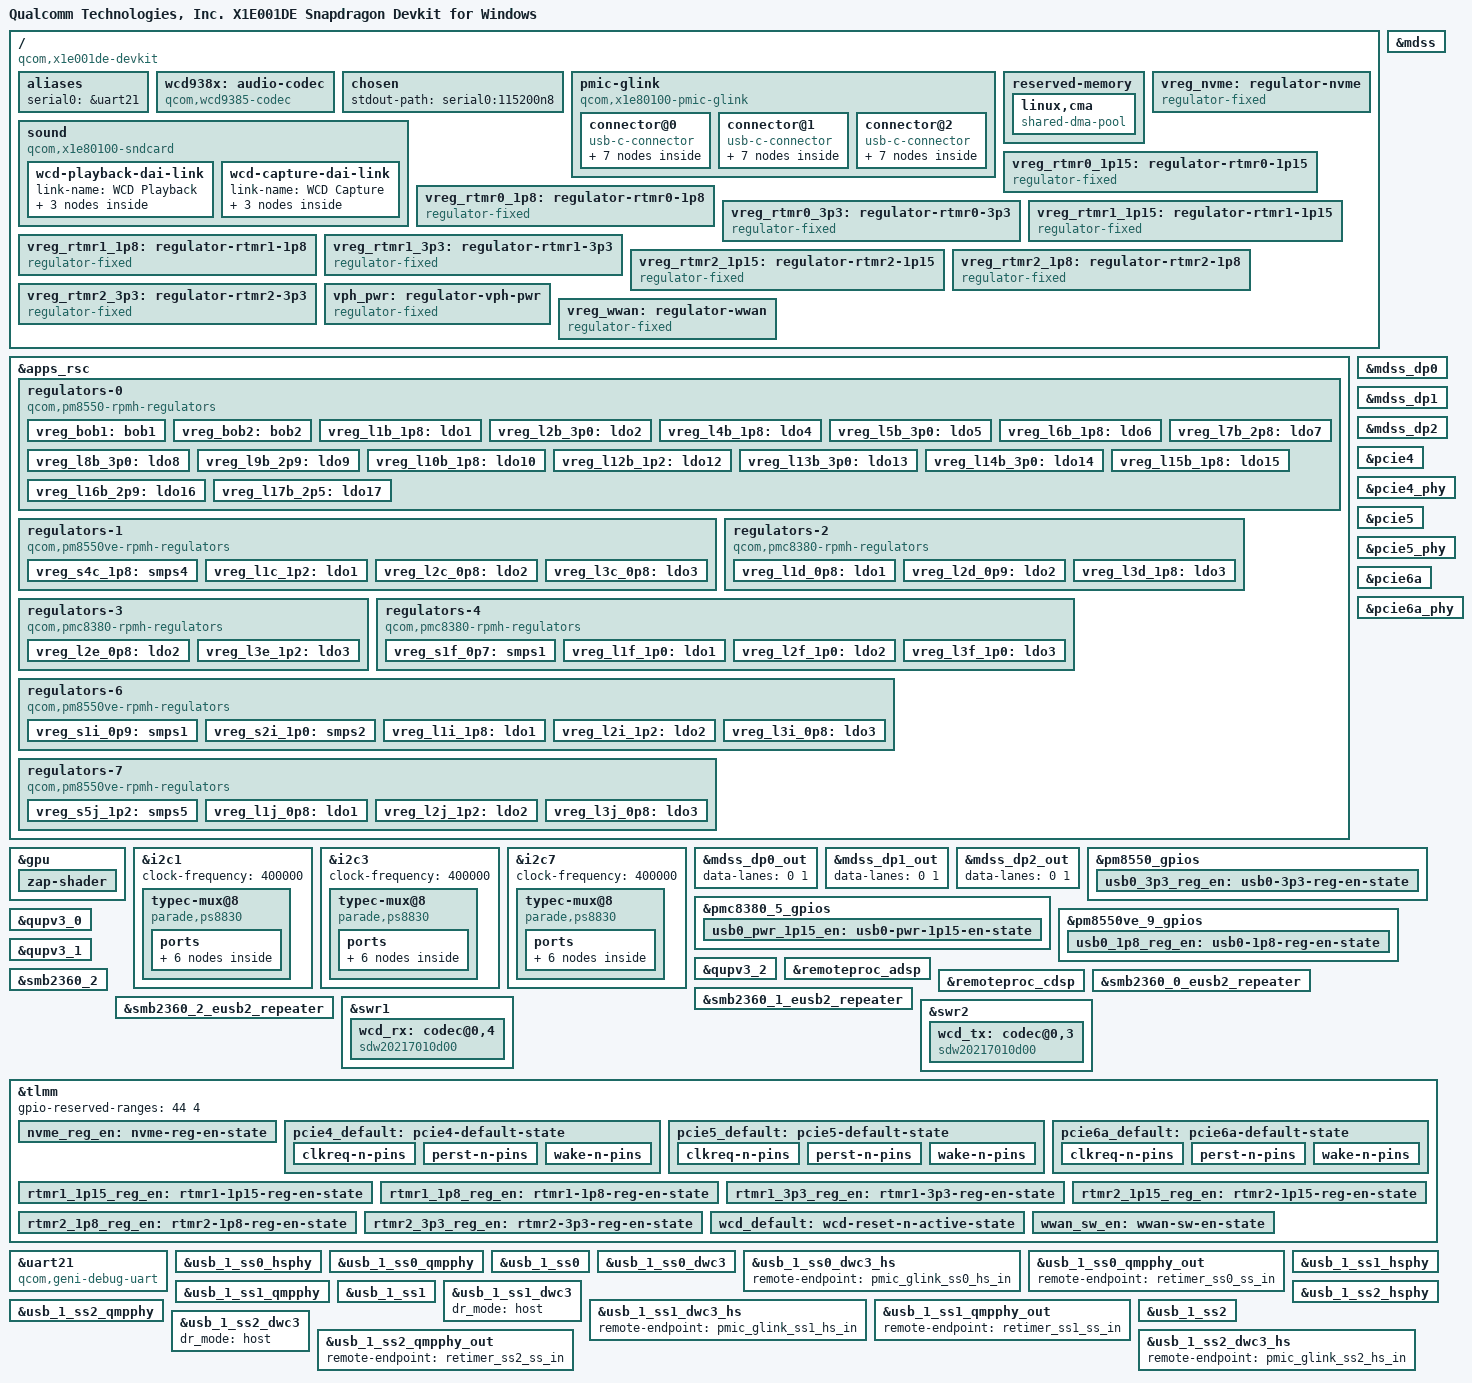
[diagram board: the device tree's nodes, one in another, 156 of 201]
// SPDX-License-Identifier: BSD-3-Clause
/*
 * Copyright (c) 2024 Qualcomm Innovation Center, Inc. All rights reserved.
 */

/dts-v1/;

#include <dt-bindings/gpio/gpio.h>
#include <dt-bindings/regulator/qcom,rpmh-regulator.h>

#include "x1e80100.dtsi"
#include "x1e80100-pmics.dtsi"

/ {
	model = "Qualcomm Technologies, Inc. X1E001DE Snapdragon Devkit for Windows";
	compatible = "qcom,x1e001de-devkit", "qcom,x1e001de", "qcom,x1e80100";

	aliases {
		serial0 = &uart21;
	};

	wcd938x: audio-codec {
		compatible = "qcom,wcd9385-codec";

		pinctrl-names = "default";
		pinctrl-0 = <&wcd_default>;

		qcom,micbias1-microvolt = <1800000>;
		qcom,micbias2-microvolt = <1800000>;
		qcom,micbias3-microvolt = <1800000>;
		qcom,micbias4-microvolt = <1800000>;
		qcom,mbhc-buttons-vthreshold-microvolt = <75000 150000 237000 500000 500000 500000 500000 500000>;
		qcom,mbhc-headset-vthreshold-microvolt = <1700000>;
		qcom,mbhc-headphone-vthreshold-microvolt = <50000>;
		qcom,rx-device = <&wcd_rx>;
		qcom,tx-device = <&wcd_tx>;

		reset-gpios = <&tlmm 191 GPIO_ACTIVE_LOW>;

		vdd-buck-supply = <&vreg_l15b_1p8>;
		vdd-rxtx-supply = <&vreg_l15b_1p8>;
		vdd-io-supply = <&vreg_l15b_1p8>;
		vdd-mic-bias-supply = <&vreg_bob1>;

		#sound-dai-cells = <1>;
	};

	chosen {
		stdout-path = "serial0:115200n8";
	};

	pmic-glink {
		compatible = "qcom,x1e80100-pmic-glink",
			     "qcom,sm8550-pmic-glink",
			     "qcom,pmic-glink";
		#address-cells = <1>;
		#size-cells = <0>;
		orientation-gpios = <&tlmm 121 GPIO_ACTIVE_HIGH>,
				    <&tlmm 123 GPIO_ACTIVE_HIGH>,
				    <&tlmm 125 GPIO_ACTIVE_HIGH>;

		/* Back panel port closer to the RJ45 connector */
		connector@0 {
			compatible = "usb-c-connector";
			reg = <0>;
			power-role = "dual";
			data-role = "dual";

			ports {
				#address-cells = <1>;
				#size-cells = <0>;

				port@0 {
					reg = <0>;

					pmic_glink_ss0_hs_in: endpoint {
						remote-endpoint = <&usb_1_ss0_dwc3_hs>;
					};
				};

				port@1 {
					reg = <1>;

					pmic_glink_ss0_ss_in: endpoint {
						remote-endpoint = <&retimer_ss0_ss_out>;
					};
				};

				port@2 {
					reg = <2>;

					pmic_glink_ss0_con_sbu_in: endpoint {
						remote-endpoint = <&retimer_ss0_con_sbu_out>;
					};
				};
			};
		};

		/* Back panel port closer to the audio jack */
		connector@1 {
			compatible = "usb-c-connector";
			reg = <1>;
			power-role = "dual";
			data-role = "host";

			ports {
				#address-cells = <1>;
				#size-cells = <0>;

				port@0 {
					reg = <0>;

					pmic_glink_ss1_hs_in: endpoint {
						remote-endpoint = <&usb_1_ss1_dwc3_hs>;
					};
				};

				port@1 {
					reg = <1>;

					pmic_glink_ss1_ss_in: endpoint {
						remote-endpoint = <&retimer_ss1_ss_out>;
					};
				};

				port@2 {
					reg = <2>;

					pmic_glink_ss1_con_sbu_in: endpoint {
						remote-endpoint = <&retimer_ss1_con_sbu_out>;
					};
				};
			};
		};

		/* Front panel port */
		connector@2 {
			compatible = "usb-c-connector";
			reg = <2>;
			power-role = "dual";
			data-role = "host";

			ports {
				#address-cells = <1>;
				#size-cells = <0>;

				port@0 {
					reg = <0>;

					pmic_glink_ss2_hs_in: endpoint {
						remote-endpoint = <&usb_1_ss2_dwc3_hs>;
					};
				};

				port@1 {
					reg = <1>;

					pmic_glink_ss2_ss_in: endpoint {
						remote-endpoint = <&retimer_ss2_ss_out>;
					};
				};

				port@2 {
					reg = <2>;

					pmic_glink_ss2_con_sbu_in: endpoint {
						remote-endpoint = <&retimer_ss2_con_sbu_out>;
					};
				};
			};
		};
	};

	reserved-memory {
		linux,cma {
			compatible = "shared-dma-pool";
			size = <0x0 0x8000000>;
			reusable;
			linux,cma-default;
		};
	};

	sound {
		compatible = "qcom,x1e80100-sndcard";
		model = "X1E001DE-DEVKIT";
		audio-routing = "IN1_HPHL", "HPHL_OUT",
				"IN2_HPHR", "HPHR_OUT",
				"AMIC2", "MIC BIAS2",
				"TX SWR_INPUT1", "ADC2_OUTPUT";

		wcd-playback-dai-link {
			link-name = "WCD Playback";

			cpu {
				sound-dai = <&q6apmbedai RX_CODEC_DMA_RX_0>;
			};

			codec {
				sound-dai = <&wcd938x 0>, <&swr1 0>, <&lpass_rxmacro 0>;
			};

			platform {
				sound-dai = <&q6apm>;
			};
		};

		wcd-capture-dai-link {
			link-name = "WCD Capture";

			cpu {
				sound-dai = <&q6apmbedai TX_CODEC_DMA_TX_3>;
			};

			codec {
				sound-dai = <&wcd938x 1>, <&swr2 1>, <&lpass_txmacro 0>;
			};

			platform {
				sound-dai = <&q6apm>;
			};
		};
	};

	vreg_nvme: regulator-nvme {
		compatible = "regulator-fixed";

		regulator-name = "VREG_NVME_3P3";
		regulator-min-microvolt = <3300000>;
		regulator-max-microvolt = <3300000>;

		gpio = <&tlmm 18 GPIO_ACTIVE_HIGH>;
		enable-active-high;

		pinctrl-names = "default";
		pinctrl-0 = <&nvme_reg_en>;

		regulator-boot-on;
	};

	vreg_rtmr0_1p15: regulator-rtmr0-1p15 {
		compatible = "regulator-fixed";

		regulator-name = "VREG_RTMR0_1P15";
		regulator-min-microvolt = <1150000>;
		regulator-max-microvolt = <1150000>;

		gpio = <&pmc8380_5_gpios 8 GPIO_ACTIVE_HIGH>;
		enable-active-high;

		pinctrl-0 = <&usb0_pwr_1p15_en>;
		pinctrl-names = "default";

		regulator-boot-on;
	};

	vreg_rtmr0_1p8: regulator-rtmr0-1p8 {
		compatible = "regulator-fixed";

		regulator-name = "VREG_RTMR0_1P8";
		regulator-min-microvolt = <1800000>;
		regulator-max-microvolt = <1800000>;

		gpio = <&pm8550ve_9_gpios 8 GPIO_ACTIVE_HIGH>;
		enable-active-high;

		pinctrl-0 = <&usb0_1p8_reg_en>;
		pinctrl-names = "default";

		regulator-boot-on;
	};

	vreg_rtmr0_3p3: regulator-rtmr0-3p3 {
		compatible = "regulator-fixed";

		regulator-name = "VREG_RTMR0_3P3";
		regulator-min-microvolt = <3300000>;
		regulator-max-microvolt = <3300000>;

		gpio = <&pm8550_gpios 11 GPIO_ACTIVE_HIGH>;
		enable-active-high;

		pinctrl-0 = <&usb0_3p3_reg_en>;
		pinctrl-names = "default";

		regulator-boot-on;
	};

	vreg_rtmr1_1p15: regulator-rtmr1-1p15 {
		compatible = "regulator-fixed";

		regulator-name = "VREG_RTMR1_1P15";
		regulator-min-microvolt = <1150000>;
		regulator-max-microvolt = <1150000>;

		gpio = <&tlmm 188 GPIO_ACTIVE_HIGH>;
		enable-active-high;

		pinctrl-0 = <&rtmr1_1p15_reg_en>;
		pinctrl-names = "default";

		regulator-boot-on;
	};

	vreg_rtmr1_1p8: regulator-rtmr1-1p8 {
		compatible = "regulator-fixed";

		regulator-name = "VREG_RTMR1_1P8";
		regulator-min-microvolt = <1800000>;
		regulator-max-microvolt = <1800000>;

		gpio = <&tlmm 175 GPIO_ACTIVE_HIGH>;
		enable-active-high;

		pinctrl-0 = <&rtmr1_1p8_reg_en>;
		pinctrl-names = "default";

		regulator-boot-on;
	};

	vreg_rtmr1_3p3: regulator-rtmr1-3p3 {
		compatible = "regulator-fixed";

		regulator-name = "VREG_RTMR1_3P3";
		regulator-min-microvolt = <3300000>;
		regulator-max-microvolt = <3300000>;

		gpio = <&tlmm 186 GPIO_ACTIVE_HIGH>;
		enable-active-high;

		pinctrl-0 = <&rtmr1_3p3_reg_en>;
		pinctrl-names = "default";

		regulator-boot-on;
	};

	vreg_rtmr2_1p15: regulator-rtmr2-1p15 {
		compatible = "regulator-fixed";

		regulator-name = "VREG_RTMR2_1P15";
		regulator-min-microvolt = <1150000>;
		regulator-max-microvolt = <1150000>;

		gpio = <&tlmm 189 GPIO_ACTIVE_HIGH>;
		enable-active-high;

		pinctrl-0 = <&rtmr2_1p15_reg_en>;
		pinctrl-names = "default";

		regulator-boot-on;
	};

	vreg_rtmr2_1p8: regulator-rtmr2-1p8 {
		compatible = "regulator-fixed";

		regulator-name = "VREG_RTMR2_1P8";
		regulator-min-microvolt = <1800000>;
		regulator-max-microvolt = <1800000>;

		gpio = <&tlmm 126 GPIO_ACTIVE_HIGH>;
		enable-active-high;

		pinctrl-0 = <&rtmr2_1p8_reg_en>;
		pinctrl-names = "default";

		regulator-boot-on;
	};

	vreg_rtmr2_3p3: regulator-rtmr2-3p3 {
		compatible = "regulator-fixed";

		regulator-name = "VREG_RTMR2_3P3";
		regulator-min-microvolt = <3300000>;
		regulator-max-microvolt = <3300000>;

		gpio = <&tlmm 187 GPIO_ACTIVE_HIGH>;
		enable-active-high;

		pinctrl-0 = <&rtmr2_3p3_reg_en>;
		pinctrl-names = "default";

		regulator-boot-on;
	};

	vph_pwr: regulator-vph-pwr {
		compatible = "regulator-fixed";

		regulator-name = "vph_pwr";
		regulator-min-microvolt = <3700000>;
		regulator-max-microvolt = <3700000>;

		regulator-always-on;
		regulator-boot-on;
	};

	vreg_wwan: regulator-wwan {
		compatible = "regulator-fixed";

		regulator-name = "SDX_VPH_PWR";
		regulator-min-microvolt = <3300000>;
		regulator-max-microvolt = <3300000>;

		gpio = <&tlmm 221 GPIO_ACTIVE_HIGH>;
		enable-active-high;

		pinctrl-0 = <&wwan_sw_en>;
		pinctrl-names = "default";

		regulator-boot-on;
	};
};

&apps_rsc {
	regulators-0 {
		compatible = "qcom,pm8550-rpmh-regulators";
		qcom,pmic-id = "b";

		vdd-bob1-supply = <&vph_pwr>;
		vdd-bob2-supply = <&vph_pwr>;
		vdd-l1-l4-l10-supply = <&vreg_s4c_1p8>;
		vdd-l2-l13-l14-supply = <&vreg_bob1>;
		vdd-l5-l16-supply = <&vreg_bob1>;
		vdd-l6-l7-supply = <&vreg_bob2>;
		vdd-l8-l9-supply = <&vreg_bob1>;
		vdd-l12-supply = <&vreg_s5j_1p2>;
		vdd-l15-supply = <&vreg_s4c_1p8>;
		vdd-l17-supply = <&vreg_bob2>;

		vreg_bob1: bob1 {
			regulator-name = "vreg_bob1";
			regulator-min-microvolt = <3008000>;
			regulator-max-microvolt = <3960000>;
			regulator-initial-mode = <RPMH_REGULATOR_MODE_HPM>;
		};

		vreg_bob2: bob2 {
			regulator-name = "vreg_bob2";
			regulator-min-microvolt = <2504000>;
			regulator-max-microvolt = <3008000>;
			regulator-initial-mode = <RPMH_REGULATOR_MODE_HPM>;
		};

		vreg_l1b_1p8: ldo1 {
			regulator-name = "vreg_l1b_1p8";
			regulator-min-microvolt = <1800000>;
			regulator-max-microvolt = <1800000>;
			regulator-initial-mode = <RPMH_REGULATOR_MODE_HPM>;
		};

		vreg_l2b_3p0: ldo2 {
			regulator-name = "vreg_l2b_3p0";
			regulator-min-microvolt = <3072000>;
			regulator-max-microvolt = <3100000>;
			regulator-initial-mode = <RPMH_REGULATOR_MODE_HPM>;
		};

		vreg_l4b_1p8: ldo4 {
			regulator-name = "vreg_l4b_1p8";
			regulator-min-microvolt = <1800000>;
			regulator-max-microvolt = <1800000>;
			regulator-initial-mode = <RPMH_REGULATOR_MODE_HPM>;
		};

		vreg_l5b_3p0: ldo5 {
			regulator-name = "vreg_l5b_3p0";
			regulator-min-microvolt = <3000000>;
			regulator-max-microvolt = <3000000>;
			regulator-initial-mode = <RPMH_REGULATOR_MODE_HPM>;
		};

		vreg_l6b_1p8: ldo6 {
			regulator-name = "vreg_l6b_1p8";
			regulator-min-microvolt = <1800000>;
			regulator-max-microvolt = <2960000>;
			regulator-initial-mode = <RPMH_REGULATOR_MODE_HPM>;
		};

		vreg_l7b_2p8: ldo7 {
			regulator-name = "vreg_l7b_2p8";
			regulator-min-microvolt = <2800000>;
			regulator-max-microvolt = <2800000>;
			regulator-initial-mode = <RPMH_REGULATOR_MODE_HPM>;
		};

		vreg_l8b_3p0: ldo8 {
			regulator-name = "vreg_l8b_3p0";
			regulator-min-microvolt = <3072000>;
			regulator-max-microvolt = <3072000>;
			regulator-initial-mode = <RPMH_REGULATOR_MODE_HPM>;
		};

		vreg_l9b_2p9: ldo9 {
			regulator-name = "vreg_l9b_2p9";
			regulator-min-microvolt = <2960000>;
			regulator-max-microvolt = <2960000>;
			regulator-initial-mode = <RPMH_REGULATOR_MODE_HPM>;
		};

		vreg_l10b_1p8: ldo10 {
			regulator-name = "vreg_l10b_1p8";
			regulator-min-microvolt = <1800000>;
			regulator-max-microvolt = <1800000>;
			regulator-initial-mode = <RPMH_REGULATOR_MODE_HPM>;
		};

		vreg_l12b_1p2: ldo12 {
			regulator-name = "vreg_l12b_1p2";
			regulator-min-microvolt = <1200000>;
			regulator-max-microvolt = <1200000>;
			regulator-initial-mode = <RPMH_REGULATOR_MODE_HPM>;
		};

		vreg_l13b_3p0: ldo13 {
			regulator-name = "vreg_l13b_3p0";
			regulator-min-microvolt = <3072000>;
			regulator-max-microvolt = <3100000>;
			regulator-initial-mode = <RPMH_REGULATOR_MODE_HPM>;
		};

		vreg_l14b_3p0: ldo14 {
			regulator-name = "vreg_l14b_3p0";
			regulator-min-microvolt = <3072000>;
			regulator-max-microvolt = <3072000>;
			regulator-initial-mode = <RPMH_REGULATOR_MODE_HPM>;
		};

		vreg_l15b_1p8: ldo15 {
			regulator-name = "vreg_l15b_1p8";
			regulator-min-microvolt = <1800000>;
			regulator-max-microvolt = <1800000>;
			regulator-initial-mode = <RPMH_REGULATOR_MODE_HPM>;
		};

		vreg_l16b_2p9: ldo16 {
			regulator-name = "vreg_l16b_2p9";
			regulator-min-microvolt = <2912000>;
			regulator-max-microvolt = <2912000>;
			regulator-initial-mode = <RPMH_REGULATOR_MODE_HPM>;
		};

		vreg_l17b_2p5: ldo17 {
			regulator-name = "vreg_l17b_2p5";
			regulator-min-microvolt = <2504000>;
			regulator-max-microvolt = <2504000>;
			regulator-initial-mode = <RPMH_REGULATOR_MODE_HPM>;
		};
	};

	regulators-1 {
		compatible = "qcom,pm8550ve-rpmh-regulators";
		qcom,pmic-id = "c";

		vdd-l1-supply = <&vreg_s5j_1p2>;
		vdd-l2-supply = <&vreg_s1f_0p7>;
		vdd-l3-supply = <&vreg_s1f_0p7>;
		vdd-s4-supply = <&vph_pwr>;

		vreg_s4c_1p8: smps4 {
			regulator-name = "vreg_s4c_1p8";
			regulator-min-microvolt = <1856000>;
			regulator-max-microvolt = <2000000>;
			regulator-initial-mode = <RPMH_REGULATOR_MODE_HPM>;
		};

		vreg_l1c_1p2: ldo1 {
			regulator-name = "vreg_l1c_1p2";
			regulator-min-microvolt = <1200000>;
			regulator-max-microvolt = <1200000>;
			regulator-initial-mode = <RPMH_REGULATOR_MODE_HPM>;
		};

		vreg_l2c_0p8: ldo2 {
			regulator-name = "vreg_l2c_0p8";
			regulator-min-microvolt = <880000>;
			regulator-max-microvolt = <920000>;
			regulator-initial-mode = <RPMH_REGULATOR_MODE_HPM>;
		};

		vreg_l3c_0p8: ldo3 {
			regulator-name = "vreg_l3c_0p8";
			regulator-min-microvolt = <880000>;
			regulator-max-microvolt = <920000>;
			regulator-initial-mode = <RPMH_REGULATOR_MODE_HPM>;
		};
	};

	regulators-2 {
		compatible = "qcom,pmc8380-rpmh-regulators";
		qcom,pmic-id = "d";

		vdd-l1-supply = <&vreg_s1f_0p7>;
		vdd-l2-supply = <&vreg_s1f_0p7>;
		vdd-l3-supply = <&vreg_s4c_1p8>;
		vdd-s1-supply = <&vph_pwr>;

		vreg_l1d_0p8: ldo1 {
			regulator-name = "vreg_l1d_0p8";
			regulator-min-microvolt = <880000>;
			regulator-max-microvolt = <920000>;
			regulator-initial-mode = <RPMH_REGULATOR_MODE_HPM>;
		};

		vreg_l2d_0p9: ldo2 {
			regulator-name = "vreg_l2d_0p9";
			regulator-min-microvolt = <912000>;
			regulator-max-microvolt = <920000>;
			regulator-initial-mode = <RPMH_REGULATOR_MODE_HPM>;
		};

		vreg_l3d_1p8: ldo3 {
			regulator-name = "vreg_l3d_1p8";
			regulator-min-microvolt = <1800000>;
			regulator-max-microvolt = <1800000>;
			regulator-initial-mode = <RPMH_REGULATOR_MODE_HPM>;
		};
	};

	regulators-3 {
		compatible = "qcom,pmc8380-rpmh-regulators";
		qcom,pmic-id = "e";

		vdd-l2-supply = <&vreg_s1f_0p7>;
		vdd-l3-supply = <&vreg_s5j_1p2>;

		vreg_l2e_0p8: ldo2 {
			regulator-name = "vreg_l2e_0p8";
			regulator-min-microvolt = <880000>;
			regulator-max-microvolt = <920000>;
			regulator-initial-mode = <RPMH_REGULATOR_MODE_HPM>;
		};

		vreg_l3e_1p2: ldo3 {
			regulator-name = "vreg_l3e_1p2";
			regulator-min-microvolt = <1200000>;
			regulator-max-microvolt = <1200000>;
			regulator-initial-mode = <RPMH_REGULATOR_MODE_HPM>;
		};
	};

	regulators-4 {
		compatible = "qcom,pmc8380-rpmh-regulators";
		qcom,pmic-id = "f";

		vdd-l1-supply = <&vreg_s5j_1p2>;
		vdd-l2-supply = <&vreg_s5j_1p2>;
		vdd-l3-supply = <&vreg_s5j_1p2>;
		vdd-s1-supply = <&vph_pwr>;

		vreg_s1f_0p7: smps1 {
			regulator-name = "vreg_s1f_0p7";
			regulator-min-microvolt = <700000>;
			regulator-max-microvolt = <1100000>;
			regulator-initial-mode = <RPMH_REGULATOR_MODE_HPM>;
		};

		vreg_l1f_1p0: ldo1 {
			regulator-name = "vreg_l1f_1p0";
			regulator-min-microvolt = <1024000>;
			regulator-max-microvolt = <1024000>;
			regulator-initial-mode = <RPMH_REGULATOR_MODE_HPM>;
		};

		vreg_l2f_1p0: ldo2 {
			regulator-name = "vreg_l2f_1p0";
			regulator-min-microvolt = <1024000>;
			regulator-max-microvolt = <1024000>;
			regulator-initial-mode = <RPMH_REGULATOR_MODE_HPM>;
		};

		vreg_l3f_1p0: ldo3 {
			regulator-name = "vreg_l3f_1p0";
			regulator-min-microvolt = <1024000>;
			regulator-max-microvolt = <1024000>;
			regulator-initial-mode = <RPMH_REGULATOR_MODE_HPM>;
		};
	};

	regulators-6 {
		compatible = "qcom,pm8550ve-rpmh-regulators";
		qcom,pmic-id = "i";

		vdd-l1-supply = <&vreg_s4c_1p8>;
		vdd-l2-supply = <&vreg_s5j_1p2>;
		vdd-l3-supply = <&vreg_s1f_0p7>;
		vdd-s1-supply = <&vph_pwr>;
		vdd-s2-supply = <&vph_pwr>;

		vreg_s1i_0p9: smps1 {
			regulator-name = "vreg_s1i_0p9";
			regulator-min-microvolt = <900000>;
			regulator-max-microvolt = <920000>;
			regulator-initial-mode = <RPMH_REGULATOR_MODE_HPM>;
		};

		vreg_s2i_1p0: smps2 {
			regulator-name = "vreg_s2i_1p0";
			regulator-min-microvolt = <1000000>;
			regulator-max-microvolt = <1100000>;
			regulator-initial-mode = <RPMH_REGULATOR_MODE_HPM>;
		};

		vreg_l1i_1p8: ldo1 {
			regulator-name = "vreg_l1i_1p8";
			regulator-min-microvolt = <1800000>;
			regulator-max-microvolt = <1800000>;
			regulator-initial-mode = <RPMH_REGULATOR_MODE_HPM>;
		};

		vreg_l2i_1p2: ldo2 {
			regulator-name = "vreg_l2i_1p2";
			regulator-min-microvolt = <1200000>;
			regulator-max-microvolt = <1200000>;
			regulator-initial-mode = <RPMH_REGULATOR_MODE_HPM>;
		};

		vreg_l3i_0p8: ldo3 {
			regulator-name = "vreg_l3i_0p8";
			regulator-min-microvolt = <880000>;
			regulator-max-microvolt = <920000>;
			regulator-initial-mode = <RPMH_REGULATOR_MODE_HPM>;
		};
	};

	regulators-7 {
		compatible = "qcom,pm8550ve-rpmh-regulators";
		qcom,pmic-id = "j";

		vdd-l1-supply = <&vreg_s1f_0p7>;
		vdd-l2-supply = <&vreg_s5j_1p2>;
		vdd-l3-supply = <&vreg_s1f_0p7>;
		vdd-s5-supply = <&vph_pwr>;

		vreg_s5j_1p2: smps5 {
			regulator-name = "vreg_s5j_1p2";
			regulator-min-microvolt = <1256000>;
			regulator-max-microvolt = <1304000>;
			regulator-initial-mode = <RPMH_REGULATOR_MODE_HPM>;
		};

		vreg_l1j_0p8: ldo1 {
			regulator-name = "vreg_l1j_0p8";
			regulator-min-microvolt = <880000>;
			regulator-max-microvolt = <920000>;
			regulator-initial-mode = <RPMH_REGULATOR_MODE_HPM>;
		};

		vreg_l2j_1p2: ldo2 {
			regulator-name = "vreg_l2j_1p2";
			regulator-min-microvolt = <1200000>;
			regulator-max-microvolt = <1200000>;
			regulator-initial-mode = <RPMH_REGULATOR_MODE_HPM>;
		};

		vreg_l3j_0p8: ldo3 {
			regulator-name = "vreg_l3j_0p8";
			regulator-min-microvolt = <880000>;
			regulator-max-microvolt = <920000>;
			regulator-initial-mode = <RPMH_REGULATOR_MODE_HPM>;
		};
	};
};

&gpu {
	status = "okay";

	zap-shader {
		firmware-name = "qcom/x1e80100/Thundercomm/DEVKIT/qcdxkmsuc8380.mbn";
	};
};

&i2c1 {
	clock-frequency = <400000>;

	status = "okay";

	typec-mux@8 {
		compatible = "parade,ps8830";
		reg = <0x08>;

		clocks = <&rpmhcc RPMH_RF_CLK5>;
		clock-names = "xo";

		vdd-supply = <&vreg_rtmr2_1p15>;
		vdd33-supply = <&vreg_rtmr2_3p3>;
		vdd33-cap-supply = <&vreg_rtmr2_3p3>;
		vddar-supply = <&vreg_rtmr2_1p15>;
		vddat-supply = <&vreg_rtmr2_1p15>;
		vddio-supply = <&vreg_rtmr2_1p8>;

		reset-gpios = <&tlmm 185 GPIO_ACTIVE_HIGH>;

		orientation-switch;
		retimer-switch;

		ports {
			#address-cells = <1>;
			#size-cells = <0>;

			port@0 {
				reg = <0>;

				retimer_ss2_ss_out: endpoint {
					remote-endpoint = <&pmic_glink_ss2_ss_in>;
				};
			};

			port@1 {
				reg = <1>;

				retimer_ss2_ss_in: endpoint {
					remote-endpoint = <&usb_1_ss2_qmpphy_out>;
				};
			};

			port@2 {
				reg = <2>;

				retimer_ss2_con_sbu_out: endpoint {
					remote-endpoint = <&pmic_glink_ss2_con_sbu_in>;
				};
			};
		};
	};
};

&i2c3 {
	clock-frequency = <400000>;

	status = "okay";

	typec-mux@8 {
		compatible = "parade,ps8830";
		reg = <0x08>;

		clocks = <&rpmhcc RPMH_RF_CLK3>;
		clock-names = "xo";

		vdd-supply = <&vreg_rtmr0_1p15>;
		vdd33-supply = <&vreg_rtmr0_3p3>;
		vdd33-cap-supply = <&vreg_rtmr0_3p3>;
		vddar-supply = <&vreg_rtmr0_1p15>;
		vddat-supply = <&vreg_rtmr0_1p15>;
		vddio-supply = <&vreg_rtmr0_1p8>;

		reset-gpios = <&pm8550_gpios 10 GPIO_ACTIVE_HIGH>;

		retimer-switch;
		orientation-switch;

		ports {
			#address-cells = <1>;
			#size-cells = <0>;

			port@0 {
				reg = <0>;

				retimer_ss0_ss_out: endpoint {
					remote-endpoint = <&pmic_glink_ss0_ss_in>;
				};
			};

			port@1 {
				reg = <1>;

				retimer_ss0_ss_in: endpoint {
					remote-endpoint = <&usb_1_ss0_qmpphy_out>;
				};
			};

			port@2 {
				reg = <2>;

				retimer_ss0_con_sbu_out: endpoint {
					remote-endpoint = <&pmic_glink_ss0_con_sbu_in>;
				};
			};
		};
	};
};

&i2c7 {
	clock-frequency = <400000>;

	status = "okay";

	typec-mux@8 {
		compatible = "parade,ps8830";
		reg = <0x8>;

		clocks = <&rpmhcc RPMH_RF_CLK4>;
		clock-names = "xo";

		vdd-supply = <&vreg_rtmr1_1p15>;
		vdd33-supply = <&vreg_rtmr1_3p3>;
		vdd33-cap-supply = <&vreg_rtmr1_3p3>;
		vddar-supply = <&vreg_rtmr1_1p15>;
		vddat-supply = <&vreg_rtmr1_1p15>;
		vddio-supply = <&vreg_rtmr1_1p8>;

		reset-gpios = <&tlmm 176 GPIO_ACTIVE_HIGH>;

		retimer-switch;
		orientation-switch;

		ports {
			#address-cells = <1>;
			#size-cells = <0>;

			port@0 {
				reg = <0>;

				retimer_ss1_ss_out: endpoint {
					remote-endpoint = <&pmic_glink_ss1_ss_in>;
				};
			};

			port@1 {
				reg = <1>;

				retimer_ss1_ss_in: endpoint {
					remote-endpoint = <&usb_1_ss1_qmpphy_out>;
				};
			};

			port@2 {
				reg = <2>;

				retimer_ss1_con_sbu_out: endpoint {
					remote-endpoint = <&pmic_glink_ss1_con_sbu_in>;
				};
			};
		};
	};
};

&mdss {
	status = "okay";
};

&mdss_dp0 {
	status = "okay";
};

&mdss_dp0_out {
	data-lanes = <0 1>;
};

&mdss_dp1 {
	status = "okay";
};

&mdss_dp1_out {
	data-lanes = <0 1>;
};

&mdss_dp2 {
	status = "okay";
};

&mdss_dp2_out {
	data-lanes = <0 1>;
};

&pcie4 {
	perst-gpios = <&tlmm 146 GPIO_ACTIVE_LOW>;
	wake-gpios = <&tlmm 148 GPIO_ACTIVE_LOW>;

	pinctrl-0 = <&pcie4_default>;
	pinctrl-names = "default";

	status = "okay";
};

&pcie4_phy {
	vdda-phy-supply = <&vreg_l3i_0p8>;
	vdda-pll-supply = <&vreg_l3e_1p2>;

	status = "okay";
};

&pcie5 {
	perst-gpios = <&tlmm 149 GPIO_ACTIVE_LOW>;
	wake-gpios = <&tlmm 151 GPIO_ACTIVE_LOW>;

	vddpe-3v3-supply = <&vreg_wwan>;

	pinctrl-0 = <&pcie5_default>;
	pinctrl-names = "default";

	status = "okay";
};

&pcie5_phy {
	vdda-phy-supply = <&vreg_l3i_0p8>;
	vdda-pll-supply = <&vreg_l3e_1p2>;

	status = "okay";
};

&pcie6a {
	perst-gpios = <&tlmm 152 GPIO_ACTIVE_LOW>;
	wake-gpios = <&tlmm 154 GPIO_ACTIVE_LOW>;

	vddpe-3v3-supply = <&vreg_nvme>;

	pinctrl-names = "default";
	pinctrl-0 = <&pcie6a_default>;

	status = "okay";
};

&pcie6a_phy {
	vdda-phy-supply = <&vreg_l1d_0p8>;
	vdda-pll-supply = <&vreg_l2j_1p2>;

	status = "okay";
};

&pm8550_gpios {
	usb0_3p3_reg_en: usb0-3p3-reg-en-state {
		pins = "gpio11";
		function = "normal";
	};
};

&pmc8380_5_gpios {
	usb0_pwr_1p15_en: usb0-pwr-1p15-en-state {
		pins = "gpio8";
		function = "normal";
	};
};

&pm8550ve_9_gpios {
	usb0_1p8_reg_en: usb0-1p8-reg-en-state {
		pins = "gpio8";
		function = "normal";
	};
};

&qupv3_0 {
	status = "okay";
};

&qupv3_1 {
	status = "okay";
};

&qupv3_2 {
	status = "okay";
};

&remoteproc_adsp {
	firmware-name = "qcom/x1e80100/Thundercomm/DEVKIT/qcadsp8380.mbn",
			"qcom/x1e80100/Thundercomm/DEVKIT/adsp_dtbs.elf";

	status = "okay";
};

&remoteproc_cdsp {
	firmware-name = "qcom/x1e80100/Thundercomm/DEVKIT/qccdsp8380.mbn",
			"qcom/x1e80100/Thundercomm/DEVKIT/cdsp_dtbs.elf";

	status = "okay";
};

&smb2360_0_eusb2_repeater {
	vdd18-supply = <&vreg_l3d_1p8>;
	vdd3-supply = <&vreg_l2b_3p0>;
};

&smb2360_1_eusb2_repeater {
	vdd18-supply = <&vreg_l3d_1p8>;
	vdd3-supply = <&vreg_l14b_3p0>;
};

&smb2360_2 {
	status = "okay";
};

&smb2360_2_eusb2_repeater {
	vdd18-supply = <&vreg_l3d_1p8>;
	vdd3-supply = <&vreg_l8b_3p0>;
};

&swr1 {
	status = "okay";

	/* WCD9385 RX */
	wcd_rx: codec@0,4 {
		compatible = "sdw20217010d00";
		reg = <0 4>;
		qcom,rx-port-mapping = <1 2 3 4 5>;
	};
};

&swr2 {
	status = "okay";

	/* WCD9385 TX */
	wcd_tx: codec@0,3 {
		compatible = "sdw20217010d00";
		reg = <0 3>;
		qcom,tx-port-mapping = <2 2 3 4>;
	};
};

&tlmm {
	gpio-reserved-ranges = <44 4>; /* SPI (TPM) */

	nvme_reg_en: nvme-reg-en-state {
		pins = "gpio18";
		function = "gpio";
		drive-strength = <2>;
		bias-disable;
	};

	pcie4_default: pcie4-default-state {
		clkreq-n-pins {
			pins = "gpio147";
			function = "pcie4_clk";
			drive-strength = <2>;
			bias-pull-up;
		};

		perst-n-pins {
			pins = "gpio146";
			function = "gpio";
			drive-strength = <2>;
			bias-disable;
		};

		wake-n-pins {
			pins = "gpio148";
			function = "gpio";
			drive-strength = <2>;
			bias-pull-up;
		};
	};

	pcie5_default: pcie5-default-state {
		clkreq-n-pins {
			pins = "gpio150";
			function = "pcie5_clk";
			drive-strength = <2>;
			bias-pull-up;
		};

		perst-n-pins {
			pins = "gpio149";
			function = "gpio";
			drive-strength = <2>;
			bias-disable;
		};

		wake-n-pins {
			pins = "gpio151";
			function = "gpio";
			drive-strength = <2>;
			bias-pull-up;
		};
	};

	pcie6a_default: pcie6a-default-state {
		clkreq-n-pins {
			pins = "gpio153";
			function = "pcie6a_clk";
			drive-strength = <2>;
			bias-pull-up;
		};

		perst-n-pins {
			pins = "gpio152";
			function = "gpio";
			drive-strength = <2>;
			bias-disable;
		};

		wake-n-pins {
			pins = "gpio154";
			function = "gpio";
			drive-strength = <2>;
			bias-pull-up;
		};
	};

	rtmr1_1p15_reg_en: rtmr1-1p15-reg-en-state {
		pins = "gpio188";
		function = "gpio";
		drive-strength = <2>;
		bias-disable;
	};

	rtmr1_1p8_reg_en: rtmr1-1p8-reg-en-state {
		pins = "gpio175";
		function = "gpio";
		drive-strength = <2>;
		bias-disable;
	};

	rtmr1_3p3_reg_en: rtmr1-3p3-reg-en-state {
		pins = "gpio186";
		function = "gpio";
		drive-strength = <2>;
		bias-disable;
	};

	rtmr2_1p15_reg_en: rtmr2-1p15-reg-en-state {
		pins = "gpio189";
		function = "gpio";
		drive-strength = <2>;
		bias-disable;
	};

	rtmr2_1p8_reg_en: rtmr2-1p8-reg-en-state {
		pins = "gpio126";
		function = "gpio";
		drive-strength = <2>;
		bias-disable;
	};

	rtmr2_3p3_reg_en: rtmr2-3p3-reg-en-state {
		pins = "gpio187";
		function = "gpio";
		drive-strength = <2>;
		bias-disable;
	};

	wcd_default: wcd-reset-n-active-state {
		pins = "gpio191";
		function = "gpio";
		drive-strength = <16>;
		bias-disable;
		output-low;
	};

	wwan_sw_en: wwan-sw-en-state {
		pins = "gpio221";
		function = "gpio";
		drive-strength = <4>;
		bias-disable;
	};
};

&uart21 {
	compatible = "qcom,geni-debug-uart";
	status = "okay";
};

&usb_1_ss0_hsphy {
	vdd-supply = <&vreg_l3j_0p8>;
	vdda12-supply = <&vreg_l2j_1p2>;

	phys = <&smb2360_0_eusb2_repeater>;

	status = "okay";
};

&usb_1_ss0_qmpphy {
	vdda-phy-supply = <&vreg_l3e_1p2>;
	vdda-pll-supply = <&vreg_l1j_0p8>;

	status = "okay";
};

&usb_1_ss0 {
	status = "okay";
};

&usb_1_ss0_dwc3 {
	dr_mode = "otg";
	usb-role-switch;
};

&usb_1_ss0_dwc3_hs {
	remote-endpoint = <&pmic_glink_ss0_hs_in>;
};

&usb_1_ss0_qmpphy_out {
	remote-endpoint = <&retimer_ss0_ss_in>;
};

&usb_1_ss1_hsphy {
	vdd-supply = <&vreg_l3j_0p8>;
	vdda12-supply = <&vreg_l2j_1p2>;

	phys = <&smb2360_1_eusb2_repeater>;

	status = "okay";
};

&usb_1_ss1_qmpphy {
	vdda-phy-supply = <&vreg_l3e_1p2>;
	vdda-pll-supply = <&vreg_l2d_0p9>;

	status = "okay";
};

&usb_1_ss1 {
	status = "okay";
};

&usb_1_ss1_dwc3 {
	dr_mode = "host";
};

&usb_1_ss1_dwc3_hs {
	remote-endpoint = <&pmic_glink_ss1_hs_in>;
};

&usb_1_ss1_qmpphy_out {
	remote-endpoint = <&retimer_ss1_ss_in>;
};

&usb_1_ss2_hsphy {
	vdd-supply = <&vreg_l3j_0p8>;
	vdda12-supply = <&vreg_l2j_1p2>;

	phys = <&smb2360_2_eusb2_repeater>;

	status = "okay";
};

&usb_1_ss2_qmpphy {
	vdda-phy-supply = <&vreg_l3e_1p2>;
	vdda-pll-supply = <&vreg_l2d_0p9>;

	status = "okay";
};

&usb_1_ss2 {
	status = "okay";
};

&usb_1_ss2_dwc3 {
	dr_mode = "host";
};

&usb_1_ss2_dwc3_hs {
	remote-endpoint = <&pmic_glink_ss2_hs_in>;
};

&usb_1_ss2_qmpphy_out {
	remote-endpoint = <&retimer_ss2_ss_in>;
};
